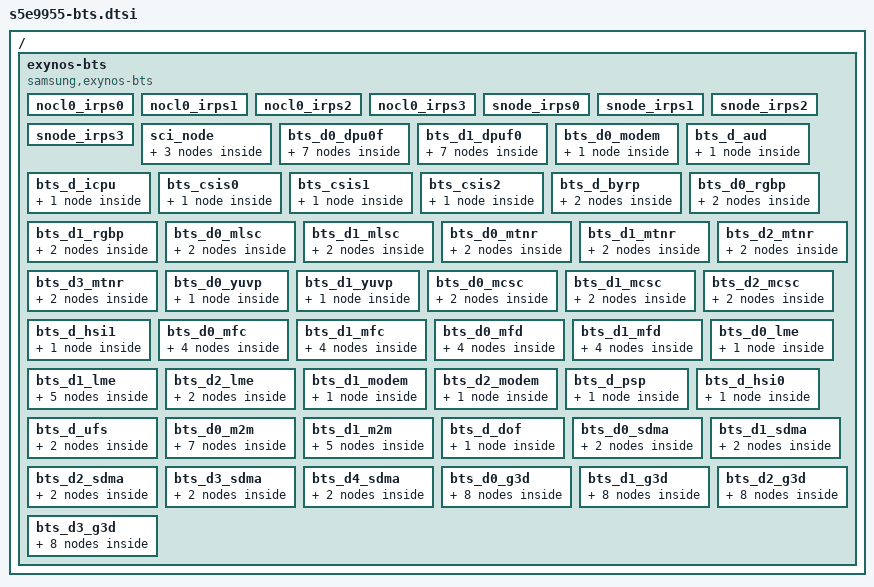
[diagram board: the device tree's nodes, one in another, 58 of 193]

/* SAMSUNG EXYNOS SoC BTS device tree source
 *
 * Copyright (c) 2018 Samsung Electronics Co., Ltd.
 *		http://www.samsung.com
 *
 * SAMSUNG EXYNOS SoC BTS device nodes are listed in this file.
 * EXYNOS based board files should include this file.
 *
 * This program is free software; you can redistribute it and/or modify
 * it under the terms of the GNU General Public License version 2 as
 * published by the Free Software Foundation.
 *
 */

#include <dt-bindings/soc/samsung/exynos-bts.h>

/*
 * TREX_D_NOCL0		0x2A070000
 * TREX_D_NOCL1		0x2B070000
 * TREX_D_NOCL2A	0x2B8E0000
 * TREX_D_NOCL2B	0x2C060000
 * TREX_D_SDMA		0x214F0000
 * SCI			0x2A060000
 * TREX_D_G3D		0x221A0000
 */

/ {
	exynos-bts {
		compatible = "samsung,exynos-bts";
		esca-ipc-channel = <ESCA_IPC_PHY__SCI>;
		#address-cells = <2>;
		#size-cells = <1>;
		ranges;

		list-scen = "default",
			"ufs_performance",
			"cp_throughput",
			"mfc_uhd",
			"mfc_uhd_10bit",
			"mfc_8k_dec30",
			"gdc_8k_8b_30",
			"gdc_8k_8b_60",
			"g3d_heavy",
			"g3d_performance",
			"dp_default",
			"camera_default",
			"npu_normal",
			"mfc_uhd_enc60",
			"camera_heavy",
			"npu_performance";

	        /* num_channel, mif_bus_width, bus_width, mif_util, int_util*/
	        bw_params = <4 16 32 70 70>;

		/* IRPS0/1/2/3 SCI_CTL_SCI_CTRL*/
		nocl0_irps0 {
			#address-cells = <2>;
			#size-cells = <1>;
			ranges;
			reg = <0x0 0x2A07A000 0x40>;
			status = "okay";
			bts-type = <TREX_BTS>;
		};
		nocl0_irps1 {
			reg = <0x0 0x2A07A040 0x40>;
			status = "okay";
			bts-type = <TREX_BTS>;
		};
		nocl0_irps2 {
			reg = <0x0 0x2A07A080 0x40>;
			status = "okay";
			bts-type = <TREX_BTS>;
		};
		nocl0_irps3 {
			reg = <0x0 0x2A07A0C0 0x40>;
			status = "okay";
			bts-type = <TREX_BTS>;
		};
		/* QMAX THRESHOLD */
//		snode_dp {
//			reg = <0x0 0x229EB040 0x8>;
//			status = "okay";
//			bts-type = <BUSC_BTS>;
//		};
		snode_irps0 {
			reg = <0x0 0x2A07B000 0x8>;
			status = "okay";
			bts-type = <BUSC_BTS>;
		};
		snode_irps1 {
			reg = <0x0 0x2A07B010 0x8>;
			status = "okay";
			bts-type = <BUSC_BTS>;
		};
		snode_irps2 {
			reg = <0x0 0x2A07B020 0x8>;
			status = "okay";
			bts-type = <BUSC_BTS>;
		};
		snode_irps3 {
			reg = <0x0 0x2A07B030 0x8>;
			status = "okay";
			bts-type = <BUSC_BTS>;
		};
		sci_node {
			reg = <0x0 0x2A060100 0x100>;
			status = "okay";
			bts-type = <SCI_BTS>;
			default {
				stat_on = <1>;
				rmo = <0x0>;
				wmo = <0x0>;
				hurrylevel3mo_0 = <0x88>;
				hurrylevel3mo_1 = <0x88>;
			};
			camera_default {
				stat_on = <1>;
				rmo = <0x8>;
				wmo = <0x8>;
				hurrylevel3mo_0 = <0x88>;
				hurrylevel3mo_1 = <0x88>;
			};
			camera_heavy {
				stat_on = <1>;
				rmo = <0x8>;
				wmo = <0x8>;
				hurrylevel3mo_0 = <0x88>;
				hurrylevel3mo_1 = <0x88>;
			};
		};
		/* NOCL1 D0_DPUF0 */
		bts_d0_dpu0f {
			reg = <0x0 0x2B078500 0x80>;
			status = "okay";
			bts-type = <IP_BTS>;
			default {
				stat_on = <1>;
				bypass = <0>;
				arqos = <0x8>;
				awqos = <0xC>;
				qurgent_on = <0x1>;
				qurgent_th_r = <0x20>;
				qurgent_th_w = <0x32>;
				blocking_on = <0>;
			};
			mfc_8k_dec30 {
				stat_on = <1>;
				bypass = <0>;
				arqos = <0x8>;
				awqos = <0xC>;
				rmo = <0xFFFF>;
				wmo = <0xFFFF>;
				qurgent_on = <1>;
				qurgent_th_r = <0x20>;
				qurgent_th_w = <0x32>;
				blocking_on = <0>;
			};
			camera_default {
				stat_on = <1>;
				bypass = <0>;
				arqos = <0x8>;
				awqos = <0xC>;
				rmo = <0xFFFF>;
				wmo = <0xFFFF>;
				qurgent_on = <1>;
				qurgent_th_r = <0x40>;
				blocking_on = <0>;
			};
			npu_normal {
				stat_on = <1>;
				bypass = <0>;
				arqos = <0x8>;
				awqos = <0xC>;
				rmo = <0xFFFF>;
				wmo = <0xFFFF>;
				qurgent_on = <1>;
				qurgent_th_r = <0x40>;
				blocking_on = <0>;
			};
			mfc_uhd_enc60 {
				stat_on = <1>;
				bypass = <0>;
				arqos = <0x8>;
				awqos = <0xC>;
				rmo = <0xFFFF>;
				wmo = <0xFFFF>;
				qurgent_on = <1>;
				qurgent_th_r = <0x40>;
				blocking_on = <0>;
			};
			camera_heavy {
				stat_on = <1>;
				bypass = <0>;
				arqos = <0x8>;
				awqos = <0xC>;
				rmo = <0xFFFF>;
				wmo = <0xFFFF>;
				qurgent_on = <1>;
				qurgent_th_r = <0x40>;
				blocking_on = <0>;
			};
			npu_performance {
				stat_on = <1>;
				bypass = <0>;
				arqos = <0x8>;
				awqos = <0xC>;
				rmo = <0xFFFF>;
				wmo = <0xFFFF>;
				qurgent_on = <1>;
				qurgent_th_r = <0x40>;
				blocking_on = <0>;
			};
		};
		/* NOCL1 D1_DPUF0 */
		bts_d1_dpuf0 {
			reg = <0x0 0x2B078580 0x80>;
			status = "okay";
			bts-type = <IP_BTS>;
			default {
				stat_on = <1>;
				bypass = <0>;
				arqos = <0x8>;
				awqos = <0xC>;
				qurgent_on = <0x1>;
				qurgent_th_r = <0x20>;
				qurgent_th_w = <0x32>;
				blocking_on = <0>;
			};
			mfc_8k_dec30 {
				stat_on = <1>;
				bypass = <0>;
				arqos = <0x8>;
				awqos = <0xC>;
				rmo = <0xFFFF>;
				wmo = <0xFFFF>;
				qurgent_on = <1>;
				qurgent_th_r = <0x20>;
				qurgent_th_w = <0x32>;
				blocking_on = <0>;
			};
			camera_default {
				stat_on = <1>;
				bypass = <0>;
				arqos = <0x8>;
				awqos = <0xC>;
				rmo = <0xFFFF>;
				wmo = <0xFFFF>;
				qurgent_on = <1>;
				qurgent_th_r = <0x40>;
				blocking_on = <0>;
			};
			npu_normal {
				stat_on = <1>;
				bypass = <0>;
				arqos = <0x8>;
				awqos = <0xC>;
				rmo = <0xFFFF>;
				wmo = <0xFFFF>;
				qurgent_on = <1>;
				qurgent_th_r = <0x40>;
				blocking_on = <0>;
			};
			mfc_uhd_enc60 {
				stat_on = <1>;
				bypass = <0>;
				arqos = <0x8>;
				awqos = <0xC>;
				rmo = <0xFFFF>;
				wmo = <0xFFFF>;
				qurgent_on = <1>;
				qurgent_th_r = <0x40>;
				blocking_on = <0>;
			};
			camera_heavy {
				stat_on = <1>;
				bypass = <0>;
				arqos = <0x8>;
				awqos = <0xC>;
				rmo = <0xFFFF>;
				wmo = <0xFFFF>;
				qurgent_on = <1>;
				qurgent_th_r = <0x40>;
				blocking_on = <0>;
			};
			npu_performance {
				stat_on = <1>;
				bypass = <0>;
				arqos = <0x8>;
				awqos = <0xC>;
				rmo = <0xFFFF>;
				wmo = <0xFFFF>;
				qurgent_on = <1>;
				qurgent_th_r = <0x40>;
				blocking_on = <0>;
			};
		};
		/* NOCL1 D0_MODEM */
		bts_d0_modem {
			reg = <0x0 0x2B078000 0x80>;
			status = "okay";
			bts-type = <IP_BTS>;
			default {
				stat_on = <1>;
				bypass = <0>;
				arqos = <0xC>;
				awqos = <0xC>;
				qurgent_on = <0x1>;
				qurgent_th_r = <0x14>;
				qurgent_th_w = <0x14>;
				blocking_on = <0>;
			};
		};
		/* NOCL1 D_AUD */
		bts_d_aud {
			reg = <0x0 0x2B078280 0x80>;
			status = "okay";
			bts-type = <IP_BTS>;
			default {
				stat_on = <1>;
				bypass = <0>;
				arqos = <0xC>;
				awqos = <0xC>;
				qurgent_on = <0x1>;
				qurgent_th_r = <0x14>;
				qurgent_th_w = <0x14>;
				blocking_on = <0>;
			};
		};
		/* NOCL1 D_ICPU */
		bts_d_icpu {
			reg = <0x0 0x2B078200 0x80>;
			status = "okay";
			bts-type = <IP_BTS>;
			default {
				stat_on = <1>;
				bypass = <0>;
				arqos = <0x4>;
				awqos = <0x4>;
				rmo = <0xFFFF>;
				wmo = <0xFFFF>;
				blocking_on = <0>;
			};
		};
		/* NOCL2A D0_CSIS */
		bts_csis0 {
			reg = <0x0 0x2B8E8000 0x80>;
			status = "okay";
			bts-type = <IP_BTS>;
			default {
				stat_on = <1>;
				bypass = <0>;
				arqos = <0xC>;
				awqos = <0xC>;
				qurgent_on = <0x1>;
				qurgent_ex = <0>;
				qurgent_th_r = <0x14>;
				qurgent_th_w = <0xD>;
				blocking_on = <0>;
			};
		};
		/* NOCL2A D1_CSIS */
		bts_csis1 {
			reg = <0x0 0x2B8E8080 0x80>;
			status = "okay";
			bts-type = <IP_BTS>;
			default {
				stat_on = <1>;
				bypass = <0>;
				arqos = <0xC>;
				awqos = <0xC>;
				qurgent_on = <0x1>;
				qurgent_ex = <0>;
				qurgent_th_r = <0x14>;
				qurgent_th_w = <0xD>;
				blocking_on = <0>;
			};
		};
		/* NOCL2A D2_CSIS */
		bts_csis2 {
			reg = <0x0 0x2B8E8100 0x80>;
			status = "okay";
			bts-type = <IP_BTS>;
			default {
				stat_on = <1>;
				bypass = <0>;
				arqos = <0x4>;
				awqos = <0xC>;
				qurgent_on = <0x1>;
				qurgent_ex = <0>;
				qurgent_th_r = <0xFF>;
				qurgent_th_w = <0xD>;
				blocking_on = <0>;
			};
		};
		/* NOCL2A D_BYRP */
		bts_d_byrp {
			reg = <0x0 0x2B8E8180 0x80>;
			status = "okay";
			bts-type = <IP_BTS>;
			default {
				stat_on = <1>;
				bypass = <0>;
				arqos = <0x4>;
				awqos = <0xC>;
				rmo = <0x8>;
				wmo = <0xFFFF>;
				qurgent_on = <0x1>;
				qurgent_th_r = <0xFF>;
				qurgent_th_w = <0xD>;
				blocking_on = <0>;
			};
			mfc_8k_dec30{
				stat_on = <1>;
				bypass = <0>;
				arqos = <0x4>;
				awqos = <0xC>;
				qurgent_on = <1>;
				qurgent_th_r = <0xFF>;
				qurgent_th_w = <0xD>;
				blocking_on = <0>;
			};
		};
		/* NOCL2A D0_RGBP */
		bts_d0_rgbp {
			reg = <0x0 0x2B8E8200 0x80>;
			status = "okay";
			bts-type = <IP_BTS>;
			default {
				stat_on = <1>;
				bypass = <0>;
				arqos = <0x4>;
				awqos = <0xC>;
				rmo = <0x8>;
				wmo = <0xFFFF>;
				qurgent_on = <0x1>;
				qurgent_th_r = <0xFF>;
				qurgent_th_w = <0xD>;
				blocking_on = <0>;
			};
			mfc_8k_dec30{
				stat_on = <1>;
				bypass = <0>;
				arqos = <0x4>;
				awqos = <0xC>;
				qurgent_on = <1>;
				qurgent_th_r = <0xFF>;
				qurgent_th_w = <0xD>;
				blocking_on = <0>;
			};
		};
		/* NOCL2A D1_RGBP */
		bts_d1_rgbp {
			reg = <0x0 0x2B8E8280 0x80>;
			status = "okay";
			bts-type = <IP_BTS>;
			default {
				stat_on = <1>;
				bypass = <0>;
				arqos = <0x4>;
				awqos = <0xC>;
				rmo = <0x8>;
				wmo = <0xFFFF>;
				qurgent_on = <0x1>;
				qurgent_th_r = <0xFF>;
				qurgent_th_w = <0xD>;
				blocking_on = <0>;
			};
			mfc_8k_dec30{
				stat_on = <1>;
				bypass = <0>;
				arqos = <0x4>;
				awqos = <0xC>;
				qurgent_on = <1>;
				qurgent_th_r = <0xFF>;
				qurgent_th_w = <0xD>;
				blocking_on = <0>;
			};
		};
		/* NOCL2A D0_MLSC */
		bts_d0_mlsc {
			reg = <0x0 0x2B8E8300 0x80>;
			status = "okay";
			bts-type = <IP_BTS>;
			default {
				stat_on = <1>;
				bypass = <0>;
				arqos = <0x4>;
				awqos = <0xC>;
				rmo = <0x10>;
				wmo = <0xFFFF>;
				qurgent_on = <0x1>;
				qurgent_th_r = <0xFF>;
				qurgent_th_w = <0xD>;
				blocking_on = <0>;
			};
			mfc_8k_dec30{
				stat_on = <1>;
				bypass = <0>;
				arqos = <0x4>;
				awqos = <0xC>;
				qurgent_on = <1>;
				qurgent_th_r = <0xFF>;
				qurgent_th_w = <0xD>;
				blocking_on = <0>;
			};
		};
		/* NOCL2A D1_MLSC */
		bts_d1_mlsc {
			reg = <0x0 0x2B8E8380 0x80>;
			status = "okay";
			bts-type = <IP_BTS>;
			default {
				stat_on = <1>;
				bypass = <0>;
				arqos = <0x4>;
				awqos = <0xC>;
				rmo = <0x10>;
				wmo = <0xFFFF>;
				qurgent_on = <0x1>;
				qurgent_th_r = <0xFF>;
				qurgent_th_w = <0xD>;
				blocking_on = <0>;
			};
			mfc_8k_dec30{
				stat_on = <1>;
				bypass = <0>;
				arqos = <0x4>;
				awqos = <0xC>;
				qurgent_on = <1>;
				qurgent_th_r = <0xFF>;
				qurgent_th_w = <0xD>;
				blocking_on = <0>;
			};
		};
		/* NOCL2A D0_MTNR */
		bts_d0_mtnr {
			reg = <0x0 0x2B8E8400 0x80>;
			status = "okay";
			bts-type = <IP_BTS>;
			default {
				stat_on = <1>;
				bypass = <0>;
				arqos = <0x4>;
				awqos = <0x4>;
				rmo = <0x18>;
				wmo = <0xC>;
				qurgent_on = <0>;
				blocking_on = <0>;
			};
			camera_heavy {
				stat_on = <1>;
				bypass = <0>;
				arqos = <0x4>;
				awqos = <0x4>;
				rmo = <0x30>;
				wmo = <0x30>;
				qurgent_on = <0>;
				blocking_on = <0>;
			};
		};
		/* NOCL2A D1_MTNR */
		bts_d1_mtnr {
			reg = <0x0 0x2B8E8480 0x80>;
			status = "okay";
			bts-type = <IP_BTS>;
			default {
				stat_on = <1>;
				bypass = <0>;
				arqos = <0x4>;
				awqos = <0x4>;
				rmo = <0x18>;
				wmo = <0xC>;
				qurgent_on = <0>;
				blocking_on = <0>;
			};
			camera_heavy {
				stat_on = <1>;
				bypass = <0>;
				arqos = <0x4>;
				awqos = <0x4>;
				rmo = <0x30>;
				wmo = <0x30>;
				qurgent_on = <0>;
				blocking_on = <0>;
			};
		};
		/* NOCL2A D2_MTNR */
		bts_d2_mtnr {
			reg = <0x0 0x2B8E8500 0x80>;
			status = "okay";
			bts-type = <IP_BTS>;
			default {
				stat_on = <1>;
				bypass = <0>;
				arqos = <0x4>;
				awqos = <0x4>;
				rmo = <0x18>;
				wmo = <0xC>;
				qurgent_on = <0>;
				blocking_on = <0>;
			};
			camera_heavy {
				stat_on = <1>;
				bypass = <0>;
				arqos = <0x4>;
				awqos = <0x4>;
				rmo = <0x30>;
				wmo = <0x30>;
				qurgent_on = <0>;
				blocking_on = <0>;
			};
		};
		/* NOCL2A D3_MTNR */
		bts_d3_mtnr {
			reg = <0x0 0x2B8E8580 0x80>;
			status = "okay";
			bts-type = <IP_BTS>;
			default {
				stat_on = <1>;
				bypass = <0>;
				arqos = <0x4>;
				awqos = <0x4>;
				rmo = <0x18>;
				wmo = <0xC>;
				qurgent_on = <0>;
				blocking_on = <0>;
			};
			camera_heavy {
				stat_on = <1>;
				bypass = <0>;
				arqos = <0x4>;
				awqos = <0x4>;
				rmo = <0x30>;
				wmo = <0x30>;
				qurgent_on = <0>;
				blocking_on = <0>;
			};
		};
		/* NOCL2A D0_YUVP */
		bts_d0_yuvp {
			reg = <0x0 0x2B8E8600 0x80>;
			status = "okay";
			bts-type = <IP_BTS>;
			default {
				stat_on = <1>;
				bypass = <0>;
				arqos = <0x4>;
				awqos = <0x4>;
				rmo = <0x10>;
				wmo = <0x10>;
				qurgent_on = <0>;
				blocking_on = <0>;
			};
		};
		/* NOCL2A D1_YUVP */
		bts_d1_yuvp {
			reg = <0x0 0x2B8E8680 0x80>;
			status = "okay";
			bts-type = <IP_BTS>;
			default {
				stat_on = <1>;
				bypass = <0>;
				arqos = <0x4>;
				awqos = <0x4>;
				rmo = <0x10>;
				wmo = <0x10>;
				qurgent_on = <0>;
				blocking_on = <0>;
			};
		};
		/* NOCL2A D0_MCSC */
		bts_d0_mcsc {
			reg = <0x0 0x2B8E8700 0x80>;
			status = "okay";
			bts-type = <IP_BTS>;
			default {
				stat_on = <1>;
				bypass = <0>;
				arqos = <0x4>;
				awqos = <0x4>;
				rmo = <0x18>;
				wmo = <0xC>;
				qurgent_on = <0>;
				blocking_on = <0>;
			};
			camera_heavy {
				stat_on = <1>;
				bypass = <0>;
				arqos = <0x4>;
				awqos = <0x4>;
				rmo = <0x30>;
				wmo = <0x30>;
				qurgent_on = <0>;
				blocking_on = <0>;
			};
		};
		/* NOCL2A D1_MCSC */
		bts_d1_mcsc {
			reg = <0x0 0x2B8E8780 0x80>;
			status = "okay";
			bts-type = <IP_BTS>;
			default {
				stat_on = <1>;
				bypass = <0>;
				arqos = <0x4>;
				awqos = <0x4>;
				rmo = <0x18>;
				wmo = <0xC>;
				qurgent_on = <0>;
				blocking_on = <0>;
			};
			camera_heavy {
				stat_on = <1>;
				bypass = <0>;
				arqos = <0x4>;
				awqos = <0x4>;
				rmo = <0x30>;
				wmo = <0x30>;
				qurgent_on = <0>;
				blocking_on = <0>;
			};
		};
		/* NOCL2A D2_MCSC */
		bts_d2_mcsc {
			reg = <0x0 0x2B8E8800 0x80>;
			status = "okay";
			bts-type = <IP_BTS>;
			default {
				stat_on = <1>;
				bypass = <0>;
				arqos = <0x4>;
				awqos = <0x4>;
				rmo = <0x18>;
				wmo = <0xC>;
				qurgent_on = <0>;
				blocking_on = <0>;
			};
			camera_heavy {
				stat_on = <1>;
				bypass = <0>;
				arqos = <0x4>;
				awqos = <0x4>;
				rmo = <0x30>;
				wmo = <0x30>;
				qurgent_on = <0>;
				blocking_on = <0>;
			};
		};
		/* NOCL2A D_HSI1 */
		bts_d_hsi1 {
			reg = <0x0 0x2B8E8880 0x80>;
			status = "okay";
			bts-type = <IP_BTS>;
			default {
				stat_on = <1>;
				bypass = <0>;
				arqos = <0x4>;
				awqos = <0x4>;
				rmo = <0x8>;
				wmo = <0x8>;
				qurgent_on = <0>;
				blocking_on = <1>;
				qmax0_limit_r = <0x1>;
				qmax0_limit_w = <0x1>;
			};
		};
		/* NOCL2B D0_MFC */
		bts_d0_mfc {
			reg = <0x0 0x2C068000 0x80>;
			status = "okay";
			bts-type = <IP_BTS>;
			default {
				stat_on = <1>;
				bypass = <0>;
				arqos = <0x4>;
				awqos = <0x4>;
				rmo = <0x20>;
				wmo = <0x20>;
				qurgent_on = <0>;
				blocking_on = <0>;
			};
			mfc_uhd_enc60 {
				stat_on = <1>;
				bypass = <0>;
				arqos = <0x4>;
				awqos = <0x4>;
				rmo = <0xFFFF>;
				wmo = <0xFFFF>;
				qurgent_on = <0>;
				blocking_on = <0>;
			};
			mfc_8k_dec30 {
				stat_on = <1>;
				bypass = <0>;
				arqos = <0x4>;
				awqos = <0x4>;
				rmo = <0xFFFF>;
				wmo = <0xFFFF>;
				qurgent_on = <0>;
				blocking_on = <0>;
			};
			camera_heavy {
				stat_on = <1>;
				bypass = <0>;
				arqos = <0x4>;
				awqos = <0x4>;
				rmo = <0x40>;
				wmo = <0x20>;
				qurgent_on = <0>;
				blocking_on = <0>;
			};
		};
		/* NOCL2B D1_MFC */
		bts_d1_mfc {
			reg = <0x0 0x2C068080 0x80>;
			status = "okay";
			bts-type = <IP_BTS>;
			default {
				stat_on = <1>;
				bypass = <0>;
				arqos = <0x4>;
				awqos = <0x4>;
				rmo = <0x20>;
				wmo = <0x20>;
				qurgent_on = <0>;
				blocking_on = <0>;
			};
			mfc_uhd_enc60 {
				stat_on = <1>;
				bypass = <0>;
				arqos = <0x4>;
				awqos = <0x4>;
				rmo = <0xFFFF>;
				wmo = <0xFFFF>;
				qurgent_on = <0>;
				blocking_on = <0>;
			};
			mfc_8k_dec30 {
				stat_on = <1>;
				bypass = <0>;
				arqos = <0x4>;
				awqos = <0x4>;
				rmo = <0xFFFF>;
				wmo = <0xFFFF>;
				qurgent_on = <0>;
				blocking_on = <0>;
			};
			camera_heavy {
				stat_on = <1>;
				bypass = <0>;
				arqos = <0x4>;
				awqos = <0x4>;
				rmo = <0x40>;
				wmo = <0x20>;
				qurgent_on = <0>;
				blocking_on = <0>;
			};
		};
		/* NOCL1B D0_MFD */
		bts_d0_mfd {
			reg = <0x0 0x2C068100 0x80>;
			status = "okay";
			bts-type = <IP_BTS>;
			default {
				stat_on = <1>;
				bypass = <0>;
				arqos = <0x4>;
				awqos = <0x4>;
				rmo = <0x20>;
				wmo = <0x20>;
				qurgent_on = <0>;
				blocking_on = <0>;
			};
			mfc_uhd_enc60 {
				stat_on = <1>;
				bypass = <0>;
				arqos = <0x4>;
				awqos = <0x4>;
				rmo = <0xFFFF>;
				wmo = <0xFFFF>;
				qurgent_on = <0>;
				blocking_on = <0>;
			};
			mfc_8k_dec30 {
				stat_on = <1>;
				bypass = <0>;
				arqos = <0x4>;
				awqos = <0x4>;
				rmo = <0xFFFF>;
				wmo = <0xFFFF>;
				qurgent_on = <0>;
				blocking_on = <0>;
			};
			camera_heavy {
				stat_on = <1>;
				bypass = <0>;
				arqos = <0x4>;
				awqos = <0x4>;
				rmo = <0x40>;
				wmo = <0x20>;
				qurgent_on = <0>;
				blocking_on = <0>;
			};
		};
		/* NOCL1B D1_MFD */
		bts_d1_mfd {
			reg = <0x0 0x2C068180 0x80>;
			status = "okay";
			bts-type = <IP_BTS>;
			default {
				stat_on = <1>;
				bypass = <0>;
				arqos = <0x4>;
				awqos = <0x4>;
				rmo = <0x20>;
				wmo = <0x20>;
				qurgent_on = <0>;
				blocking_on = <0>;
			};
			mfc_uhd_enc60 {
				stat_on = <1>;
				bypass = <0>;
				arqos = <0x4>;
				awqos = <0x4>;
				rmo = <0xFFFF>;
				wmo = <0xFFFF>;
				qurgent_on = <0>;
				blocking_on = <0>;
			};
			mfc_8k_dec30 {
				stat_on = <1>;
				bypass = <0>;
				arqos = <0x4>;
				awqos = <0x4>;
				rmo = <0xFFFF>;
				wmo = <0xFFFF>;
				qurgent_on = <0>;
				blocking_on = <0>;
			};
			camera_heavy {
				stat_on = <1>;
				bypass = <0>;
				arqos = <0x4>;
				awqos = <0x4>;
				rmo = <0x40>;
				wmo = <0x20>;
				qurgent_on = <0>;
				blocking_on = <0>;
			};
		};
		/* NOCL2B D0_LME */
		bts_d0_lme {
			reg = <0x0 0x2C068200 0x80>;
			status = "okay";
			bts-type = <IP_BTS>;
			default {
				stat_on = <1>;
				bypass = <0>;
				arqos = <0x4>;
				awqos = <0x4>;
				rmo = <0x14>;
				wmo = <0x10>;
				qurgent_on = <0>;
				blocking_on = <0>;
			};
		};
		/* NOCL1A D1_LME */
		bts_d1_lme {
			reg = <0x0 0x2C068280 0x80>;
			status = "okay";
			bts-type = <IP_BTS>;
			default {
				stat_on = <1>;
				bypass = <0>;
				arqos = <0x4>;
				awqos = <0x4>;
				rmo = <0x14>;
				wmo = <0x8>;
				qurgent_on = <0>;
				blocking_on = <0>;
			};
			mfc_8k_dec30 {
				stat_on = <1>;
				bypass = <0>;
				arqos = <0x4>;
				awqos = <0x4>;
				rmo = <0x80>;
				wmo = <0x80>;
				qurgent_on = <0>;
				blocking_on = <0>;
			};
			gdc_8k_8b_30 {
				stat_on = <1>;
				bypass = <0>;
				arqos = <0x4>;
				awqos = <0x4>;
				rmo = <0x80>;
				wmo = <0x80>;
				qurgent_on = <0>;
				blocking_on = <0>;
			};
			gdc_8k_8b_60 {
				stat_on = <1>;
				bypass = <0>;
				arqos = <0x4>;
				awqos = <0x4>;
				rmo = <0x80>;
				wmo = <0x80>;
				qurgent_on = <0>;
				blocking_on = <0>;
			};
			camera_heavy {
				stat_on = <1>;
				bypass = <0>;
				arqos = <0x4>;
				awqos = <0x4>;
				rmo = <0x28>;
				wmo = <0x10>;
				qurgent_on = <0>;
				blocking_on = <0>;
			};
		};
		/* NOCL2B D2_LME */
		bts_d2_lme {
			reg = <0x0 0x2C068300 0x80>;
			status = "okay";
			bts-type = <IP_BTS>;
			default {
				stat_on = <1>;
				bypass = <0>;
				arqos = <0x4>;
				awqos = <0x4>;
				rmo = <0xC>;
				wmo = <0xC>;
				qurgent_on = <0>;
				blocking_on = <0>;
			};
			camera_heavy {
				stat_on = <1>;
				bypass = <0>;
				arqos = <0x4>;
				awqos = <0x4>;
				rmo = <0x14>;
				wmo = <0x14>;
				qurgent_on = <0>;
				blocking_on = <0>;
			};
		};
		/* NOCL1 D1_MODEM */
		bts_d1_modem {
			reg = <0x0 0x2B078080 0x80>;
			status = "okay";
			bts-type = <IP_BTS>;
			default {
				stat_on = <1>;
				bypass = <1>;
				rmo = <0x1C>;
				wmo = <0x1C>;
				qurgent_on = <0>;
				blocking_on = <0>;
			};
		};
		/* NOCL0 D2_MODEM */
		bts_d2_modem {
			reg = <0x0 0x2B078100 0x80>;
			status = "okay";
			bts-type = <IP_BTS>;
			default {
				stat_on = <1>;
				bypass = <0>;
				arqos = <0x4>;
				awqos = <0x4>;
				rmo = <0x14>;
				wmo = <0x8>;
				qurgent_on = <0>;
				blocking_on = <0>;
			};
		};
		/* NOCL0 D_PSP */
		bts_d_psp {
			reg = <0x0 0x2B078400 0x80>;
			status = "okay";
			bts-type = <IP_BTS>;
			default {
				stat_on = <1>;
				bypass = <0>;
				arqos = <0x4>;
				awqos = <0x4>;
				rmo = <0x4>;
				wmo = <0x4>;
				qurgent_on = <0>;
				blocking_on = <0>;
			};
		};
		/* NOCL1 D_HSI0 */
		bts_d_hsi0 {
			reg = <0x0 0x2B078180 0x80>;
			status = "okay";
			bts-type = <IP_BTS>;
			default {
				stat_on = <1>;
				bypass = <0>;
				arqos = <0x4>;
				awqos = <0x4>;
				rmo = <0x4>;
				wmo = <0x4>;
				qurgent_on = <0>;
				blocking_on = <1>;
				qmax0_limit_r = <0x1>;
				qmax0_limit_w = <0x1>;
			};
		};
		/* NOCL1 D_UFS */
		bts_d_ufs {
			reg = <0x0 0x2B078480 0x80>;
			status = "okay";
			bts-type = <IP_BTS>;
			default {
				stat_on = <1>;
				bypass = <0>;
				arqos = <0x4>;
				awqos = <0x4>;
				rmo = <0x10>;
				wmo = <0xC>;
				qurgent_on = <0>;
				blocking_on = <1>;
				qmax0_limit_r = <0x1>;
				qmax0_limit_w = <0x1>;
			};
			ufs_performance {
				stat_on = <1>;
				bypass = <0>;
				arqos = <0x4>;
				awqos = <0x4>;
				rmo = <0x18>;
				wmo = <0xC>;
				qurgent_on = <0>;
				blocking_on = <1>;
				qmax0_limit_r = <0x1>;
				qmax0_limit_w = <0x1>;
			};
		};
		/* NOCL1 D0_M2M */
		bts_d0_m2m {
			reg = <0x0 0x2B078300 0x80>;
			status = "okay";
			bts-type = <IP_BTS>;
			default {
				stat_on = <1>;
				bypass = <0>;
				arqos = <0x4>;
				awqos = <0x4>;
				rmo = <0x18>;
				wmo = <0x18>;
				qurgent_on = <0>;
				blocking_on = <1>;
				qmax0_limit_r = <0x8>;
				qmax0_limit_w = <0x8>;
			};
			mfc_8k_dec30 {
				stat_on = <1>;
				bypass = <0>;
				arqos = <0x4>;
				awqos = <0x4>;
				rmo = <0x80>;
				wmo = <0x80>;
				qurgent_on = <0>;
				blocking_on = <1>;
				qmax0_limit_r = <0x8>;
				qmax0_limit_w = <0x8>;
			};
			camera_default {
				stat_on = <1>;
				bypass = <0>;
				arqos = <0x4>;
				awqos = <0x4>;
				rmo = <0x8>;
				wmo = <0x8>;
				qurgent_on = <0>;
				blocking_on = <0>;
			};
			npu_normal {
				stat_on = <1>;
				bypass = <0>;
				arqos = <0x4>;
				awqos = <0x4>;
				rmo = <0x8>;
				wmo = <0x8>;
				qurgent_on = <0>;
				blocking_on = <0>;
			};
			mfc_uhd_enc60 {
				stat_on = <1>;
				bypass = <0>;
				arqos = <0x4>;
				awqos = <0x4>;
				rmo = <0x8>;
				wmo = <0x8>;
				qurgent_on = <0>;
				blocking_on = <0>;
			};
			camera_heavy {
				stat_on = <1>;
				bypass = <0>;
				arqos = <0x4>;
				awqos = <0x4>;
				rmo = <0x20>;
				wmo = <0x20>;
				qurgent_on = <0>;
				blocking_on = <0>;
			};
			npu_performance {
				stat_on = <1>;
				bypass = <0>;
				arqos = <0x4>;
				awqos = <0x4>;
				rmo = <0x8>;
				wmo = <0x8>;
				qurgent_on = <0>;
				blocking_on = <0>;
			};
		};
		/* NOCL1 D1_M2M */
		bts_d1_m2m {
			reg = <0x0 0x2B078380 0x80>;
			status = "okay";
			bts-type = <IP_BTS>;
			default {
				stat_on = <1>;
				bypass = <0>;
				arqos = <0x4>;
				awqos = <0x4>;
				rmo = <0x1C>;
				wmo = <0xC>;
				qurgent_on = <0>;
				blocking_on = <1>;
				qmax0_limit_r = <0x8>;
				qmax0_limit_w = <0x8>;
			};
			mfc_8k_dec30 {
				stat_on = <1>;
				bypass = <0>;
				arqos = <0x4>;
				awqos = <0x4>;
				rmo = <0x80>;
				wmo = <0x80>;
				qurgent_on = <0>;
				blocking_on = <1>;
				qmax0_limit_r = <0x8>;
				qmax0_limit_w = <0x8>;
			};
			npu_normal {
				stat_on = <1>;
				bypass = <0>;
				arqos = <0x4>;
				awqos = <0x4>;
				rmo = <0x8>;
				wmo = <0x8>;
				qurgent_on = <0>;
				blocking_on = <0>;
			};
			mfc_uhd_enc60 {
				stat_on = <1>;
				bypass = <0>;
				arqos = <0x4>;
				awqos = <0x4>;
				rmo = <0x8>;
				wmo = <0x8>;
				qurgent_on = <0>;
				blocking_on = <0>;
			};
			npu_performance {
				stat_on = <1>;
				bypass = <0>;
				arqos = <0x4>;
				awqos = <0x4>;
				rmo = <0x8>;
				wmo = <0x8>;
				qurgent_on = <0>;
				blocking_on = <0>;
			};
		};
		/* NOCL1 D_DOF */
		bts_d_dof {
			reg = <0x0 0x2B078600 0x80>;
			status = "okay";
			bts-type = <IP_BTS>;
			default {
				stat_on = <1>;
				bypass = <0>;
				arqos = <0x4>;
				awqos = <0x4>;
				rmo = <0x40>;
				wmo = <0x40>;
				qurgent_on = <0>;
				blocking_on = <0>;
			};
		};
		/* TREX_D_SDMA D0_SDMA */
		bts_d0_sdma {
			reg = <0x0 0x214F8000 0x80>;
			status = "okay";
			bts-type = <IP_BTS>;
			cal-pdid = <0xB1380019>;
			default {
				stat_on = <1>;
				bypass = <0>;
				arqos = <0x4>;
				awqos = <0x4>;
				rmo = <0x50>;
				wmo = <0x50>;
				qurgent_on = <0>;
				blocking_on = <0>;
			};
			npu_performance {
				stat_on = <1>;
				bypass = <0>;
				arqos = <0x4>;
				awqos = <0x4>;
				rmo = <0xFFFF>;
				wmo = <0xFFFF>;
				qurgent_on = <0>;
				blocking_on = <0>;
			};
		};
		/* TREX_D_SDMA D1_SDMA */
		bts_d1_sdma {
			reg = <0x0 0x214F8080 0x80>;
			status = "okay";
			bts-type = <IP_BTS>;
			cal-pdid = <0xB1380019>;
			default {
				stat_on = <1>;
				bypass = <0>;
				arqos = <0x4>;
				awqos = <0x4>;
				rmo = <0x50>;
				wmo = <0x50>;
				qurgent_on = <0>;
				blocking_on = <0>;
			};
			npu_performance {
				stat_on = <1>;
				bypass = <0>;
				arqos = <0x4>;
				awqos = <0x4>;
				rmo = <0xFFFF>;
				wmo = <0xFFFF>;
				qurgent_on = <0>;
				blocking_on = <0>;
			};
		};
		/* TREX_D_SDMA D2_SDMA */
		bts_d2_sdma {
			reg = <0x0 0x214F8100 0x80>;
			status = "okay";
			bts-type = <IP_BTS>;
			cal-pdid = <0xB1380019>;
			default {
				stat_on = <1>;
				bypass = <0>;
				arqos = <0x4>;
				awqos = <0x4>;
				rmo = <0x50>;
				wmo = <0x50>;
				qurgent_on = <0>;
				blocking_on = <0>;
			};
			npu_performance {
				stat_on = <1>;
				bypass = <0>;
				arqos = <0x4>;
				awqos = <0x4>;
				rmo = <0xFFFF>;
				wmo = <0xFFFF>;
				qurgent_on = <0>;
				blocking_on = <0>;
			};
		};
		/* TREX_D_SDMA D3_SDMA */
		bts_d3_sdma {
			reg = <0x0 0x214F8180 0x80>;
			status = "okay";
			bts-type = <IP_BTS>;
			cal-pdid = <0xB1380019>;
			default {
				stat_on = <1>;
				bypass = <0>;
				arqos = <0x4>;
				awqos = <0x4>;
				rmo = <0x50>;
				wmo = <0x50>;
				qurgent_on = <0>;
				blocking_on = <0>;
			};
			npu_performance {
				stat_on = <1>;
				bypass = <0>;
				arqos = <0x4>;
				awqos = <0x4>;
				rmo = <0xFFFF>;
				wmo = <0xFFFF>;
				qurgent_on = <0>;
				blocking_on = <0>;
			};
		};
		/* TREX_D_SDMA D4_SDMA */
		bts_d4_sdma {
			reg = <0x0 0x214F8200 0x80>;
			status = "okay";
			bts-type = <IP_BTS>;
			cal-pdid = <0xB1380019>;
			default {
				stat_on = <1>;
				bypass = <0>;
				arqos = <0x4>;
				awqos = <0x4>;
				rmo = <0x50>;
				wmo = <0x50>;
				qurgent_on = <0>;
				blocking_on = <0>;
			};
			npu_performance {
				stat_on = <1>;
				bypass = <0>;
				arqos = <0x4>;
				awqos = <0x4>;
				rmo = <0xFFFF>;
				wmo = <0xFFFF>;
				qurgent_on = <0>;
				blocking_on = <0>;
			};
		};
		/* TREX_D_G3D */
		bts_d0_g3d {
			reg = <0x0 0x221A8000 0x80>;
			status = "okay";
			bts-type = <IP_BTS>;
			cal-pdid = <0xB1380007>;
			default {
				stat_on = <1>;
				bypass = <0>;
				arqos = <0x4>;
				awqos = <0x4>;
				rmo = <0x10>;
				wmo = <0x10>;
			};
			g3d_heavy {
				stat_on = <1>;
				bypass = <0>;
				arqos = <0x4>;
				awqos = <0x4>;
				rmo = <0x40>;
				wmo = <0x40>;
			};
			g3d_performance {
				stat_on = <1>;
				bypass = <0>;
				arqos = <0x4>;
				awqos = <0x4>;
				rmo = <0x40>;
				wmo = <0x40>;
			};
			mfc_uhd_enc60 {
				stat_on = <1>;
				bypass = <0>;
				arqos = <0x4>;
				awqos = <0x4>;
				rmo = <0x8>;
				wmo = <0x8>;
			};
			npu_normal {
				stat_on = <1>;
				bypass = <0>;
				arqos = <0x4>;
				awqos = <0x4>;
				rmo = <0x8>;
				wmo = <0x8>;
			};
			camera_heavy {
				stat_on = <1>;
				bypass = <0>;
				arqos = <0x4>;
				awqos = <0x4>;
				rmo = <0x8>;
				wmo = <0x8>;
			};
			camera_default {
				stat_on = <1>;
				bypass = <0>;
				arqos = <0x4>;
				awqos = <0x4>;
				rmo = <0x8>;
				wmo = <0x8>;
			};
			npu_performance {
				stat_on = <1>;
				bypass = <0>;
				arqos = <0x4>;
				awqos = <0x4>;
				rmo = <0x40>;
				wmo = <0x40>;
			};
		};
		bts_d1_g3d {
			reg = <0x0 0x221A8080 0x80>;
			status = "okay";
			bts-type = <IP_BTS>;
			cal-pdid = <0xB1380007>;
			default {
				stat_on = <1>;
				bypass = <0>;
				arqos = <0x4>;
				awqos = <0x4>;
				rmo = <0x10>;
				wmo = <0x10>;
			};
			g3d_heavy {
				stat_on = <1>;
				bypass = <0>;
				arqos = <0x4>;
				awqos = <0x4>;
				rmo = <0x40>;
				wmo = <0x40>;
			};
			g3d_performance {
				stat_on = <1>;
				bypass = <0>;
				arqos = <0x4>;
				awqos = <0x4>;
				rmo = <0x40>;
				wmo = <0x40>;
			};
			mfc_uhd_enc60 {
				stat_on = <1>;
				bypass = <0>;
				arqos = <0x4>;
				awqos = <0x4>;
				rmo = <0x8>;
				wmo = <0x8>;
			};
			npu_normal {
				stat_on = <1>;
				bypass = <0>;
				arqos = <0x4>;
				awqos = <0x4>;
				rmo = <0x8>;
				wmo = <0x8>;
			};
			camera_heavy {
				stat_on = <1>;
				bypass = <0>;
				arqos = <0x4>;
				awqos = <0x4>;
				rmo = <0x8>;
				wmo = <0x8>;
			};
			camera_default {
				stat_on = <1>;
				bypass = <0>;
				arqos = <0x4>;
				awqos = <0x4>;
				rmo = <0x8>;
				wmo = <0x8>;
			};
			npu_performance {
				stat_on = <1>;
				bypass = <0>;
				arqos = <0x4>;
				awqos = <0x4>;
				rmo = <0x40>;
				wmo = <0x40>;
			};
		};
		bts_d2_g3d {
			reg = <0x0 0x221A8100 0x80>;
			status = "okay";
			bts-type = <IP_BTS>;
			cal-pdid = <0xB1380007>;
			default {
				stat_on = <1>;
				bypass = <0>;
				arqos = <0x4>;
				awqos = <0x4>;
				rmo = <0x10>;
				wmo = <0x10>;
			};
			g3d_heavy {
				stat_on = <1>;
				bypass = <0>;
				arqos = <0x4>;
				awqos = <0x4>;
				rmo = <0x40>;
				wmo = <0x40>;
			};
			g3d_performance {
				stat_on = <1>;
				bypass = <0>;
				arqos = <0x4>;
				awqos = <0x4>;
				rmo = <0x40>;
				wmo = <0x40>;
			};
			mfc_uhd_enc60 {
				stat_on = <1>;
				bypass = <0>;
				arqos = <0x4>;
				awqos = <0x4>;
				rmo = <0x8>;
				wmo = <0x8>;
			};
			npu_normal {
				stat_on = <1>;
				bypass = <0>;
				arqos = <0x4>;
				awqos = <0x4>;
				rmo = <0x8>;
				wmo = <0x8>;
			};
			camera_heavy {
				stat_on = <1>;
				bypass = <0>;
				arqos = <0x4>;
				awqos = <0x4>;
				rmo = <0x8>;
				wmo = <0x8>;
			};
			camera_default {
				stat_on = <1>;
				bypass = <0>;
				arqos = <0x4>;
				awqos = <0x4>;
				rmo = <0x8>;
				wmo = <0x8>;
			};
			npu_performance {
				stat_on = <1>;
				bypass = <0>;
				arqos = <0x4>;
				awqos = <0x4>;
				rmo = <0x40>;
				wmo = <0x40>;
			};
		};
		bts_d3_g3d {
			reg = <0x0 0x221A8180 0x80>;
			status = "okay";
			bts-type = <IP_BTS>;
			cal-pdid = <0xB1380007>;
			default {
				stat_on = <1>;
				bypass = <0>;
				arqos = <0x4>;
				awqos = <0x4>;
				rmo = <0x10>;
				wmo = <0x10>;
			};
			g3d_heavy {
				stat_on = <1>;
				bypass = <0>;
				arqos = <0x4>;
				awqos = <0x4>;
				rmo = <0x40>;
				wmo = <0x40>;
			};
			g3d_performance {
				stat_on = <1>;
				bypass = <0>;
				arqos = <0x4>;
				awqos = <0x4>;
				rmo = <0x40>;
				wmo = <0x40>;
			};
			mfc_uhd_enc60 {
				stat_on = <1>;
				bypass = <0>;
				arqos = <0x4>;
				awqos = <0x4>;
				rmo = <0x8>;
				wmo = <0x8>;
			};
			npu_normal {
				stat_on = <1>;
				bypass = <0>;
				arqos = <0x4>;
				awqos = <0x4>;
				rmo = <0x8>;
				wmo = <0x8>;
			};
			camera_heavy {
				stat_on = <1>;
				bypass = <0>;
				arqos = <0x4>;
				awqos = <0x4>;
				rmo = <0x8>;
				wmo = <0x8>;
			};
			camera_default {
				stat_on = <1>;
				bypass = <0>;
				arqos = <0x4>;
				awqos = <0x4>;
				rmo = <0x8>;
				wmo = <0x8>;
			};
			npu_performance {
				stat_on = <1>;
				bypass = <0>;
				arqos = <0x4>;
				awqos = <0x4>;
				rmo = <0x40>;
				wmo = <0x40>;
			};
		};
	};
};
